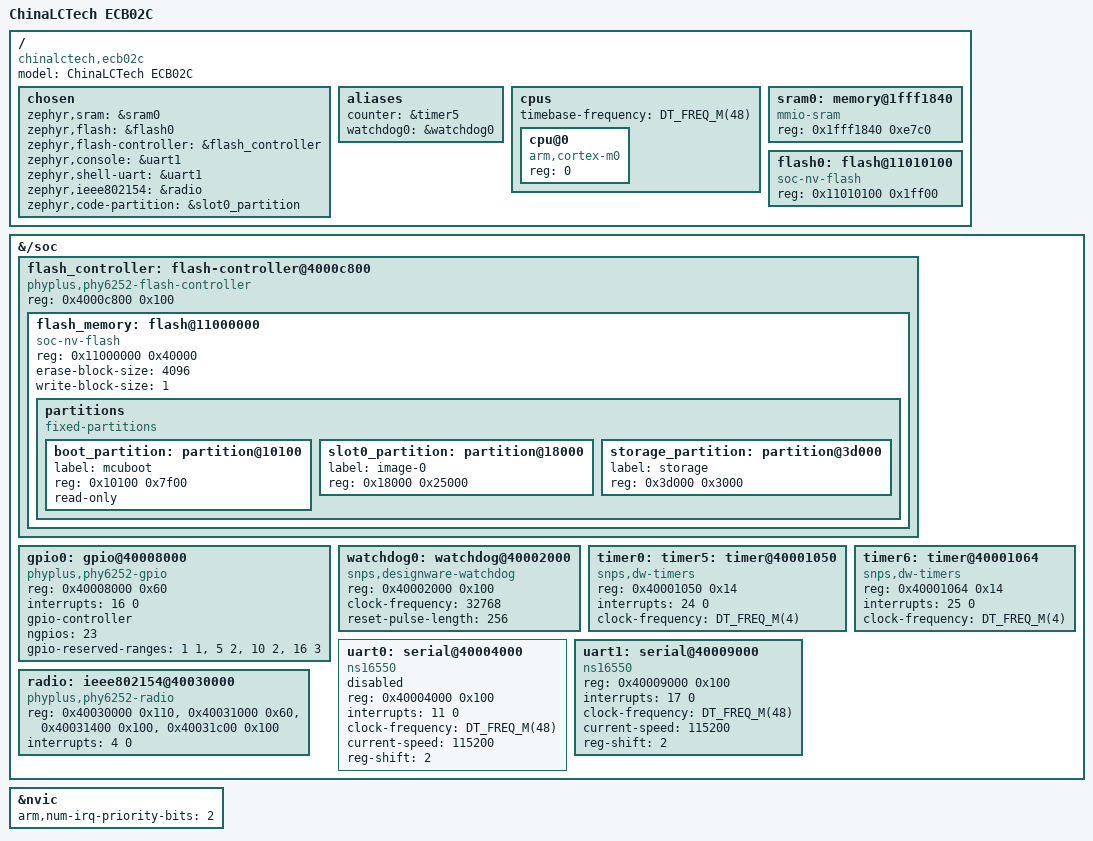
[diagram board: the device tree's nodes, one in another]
/*
 * SPDX-FileCopyrightText: Copyright The Zephyr Project Contributors
 * SPDX-License-Identifier: Apache-2.0
 */

/dts-v1/;

#include <arm/armv6-m.dtsi>
#include <freq.h>

/ {
	model = "ChinaLCTech ECB02C";
	compatible = "chinalctech,ecb02c";

	chosen {
		zephyr,sram = &sram0;
		zephyr,flash = &flash0;
		zephyr,flash-controller = &flash_controller;
		zephyr,console = &uart1;
		zephyr,shell-uart = &uart1;
		zephyr,ieee802154 = &radio;
		zephyr,code-partition = &slot0_partition;
	};

	aliases {
		counter = &timer5;
		watchdog0 = &watchdog0;
	};

	cpus {
		#address-cells = <1>;
		#size-cells = <0>;
		timebase-frequency = <DT_FREQ_M(48)>;

		cpu@0 {
			compatible = "arm,cortex-m0";
			reg = <0>;
		};
	};

	sram0: memory@1fff1840 {
		compatible = "mmio-sram";
		reg = <0x1fff1840 0xe7c0>;
	};

	flash0: flash@11010100 {
		compatible = "soc-nv-flash";
		reg = <0x11010100 0x1ff00>;
	};
};

&{/soc} {
	flash_controller: flash-controller@4000c800 {
		compatible = "phyplus,phy6252-flash-controller";
		reg = <0x4000c800 0x100>;
		#address-cells = <1>;
		#size-cells = <1>;
		status = "okay";

		flash_memory: flash@11000000 {
			compatible = "soc-nv-flash";
			reg = <0x11000000 0x40000>;
			erase-block-size = <4096>;
			write-block-size = <1>;

			partitions {
				compatible = "fixed-partitions";
				#address-cells = <1>;
				#size-cells = <1>;

				/* MCUboot at 0x10100, XIP, and the one slot of the application */
				boot_partition: partition@10100 {
					label = "mcuboot";
					reg = <0x10100 0x7f00>;
					read-only;
				};

				slot0_partition: partition@18000 {
					label = "image-0";
					reg = <0x18000 0x25000>;
				};

				storage_partition: partition@3d000 {
					label = "storage";
					reg = <0x3d000 0x3000>;
				};
			};
		};
	};

	gpio0: gpio@40008000 {
		compatible = "phyplus,phy6252-gpio";
		reg = <0x40008000 0x60>;
		interrupts = <16 0>;
		gpio-controller;
		#gpio-cells = <2>;
		ngpios = <23>;
		gpio-reserved-ranges = <1 1>, <5 2>, <10 2>, <16 3>;
		status = "okay";
	};

	watchdog0: watchdog@40002000 {
		compatible = "snps,designware-watchdog";
		reg = <0x40002000 0x100>;
		/* The RC oscillator of 32 kHz */
		clock-frequency = <32768>;
		/* As in the SDK: a pulse of 256 cycles, a shorter one does not reset the chip */
		reset-pulse-length = <256>;
		status = "okay";
	};

	timer0: timer5: timer@40001050 {
		compatible = "snps,dw-timers";
		reg = <0x40001050 0x14>;
		interrupts = <24 0>;
		clock-frequency = <DT_FREQ_M(4)>;
		status = "okay";
	};

	timer6: timer@40001064 {
		compatible = "snps,dw-timers";
		reg = <0x40001064 0x14>;
		interrupts = <25 0>;
		clock-frequency = <DT_FREQ_M(4)>;
		status = "okay";
	};

	uart0: serial@40004000 {
		compatible = "ns16550";
		reg = <0x40004000 0x100>;
		interrupts = <11 0>;
		clock-frequency = <DT_FREQ_M(48)>;
		current-speed = <115200>;
		reg-shift = <2>;
		/* P9 and P10, the pins of the boot ROM loader: the board uses UART1 */
		status = "disabled";
	};

	uart1: serial@40009000 {
		compatible = "ns16550";
		reg = <0x40009000 0x100>;
		interrupts = <17 0>;
		clock-frequency = <DT_FREQ_M(48)>;
		current-speed = <115200>;
		reg-shift = <2>;
		status = "okay";
	};

	radio: ieee802154@40030000 {
		compatible = "phyplus,phy6252-radio";
		reg = <0x40030000 0x110>, <0x40031000 0x60>,
		      <0x40031400 0x100>, <0x40031c00 0x100>;
		interrupts = <4 0>;
		status = "okay";
	};
};

&nvic {
	arm,num-irq-priority-bits = <2>;
};
